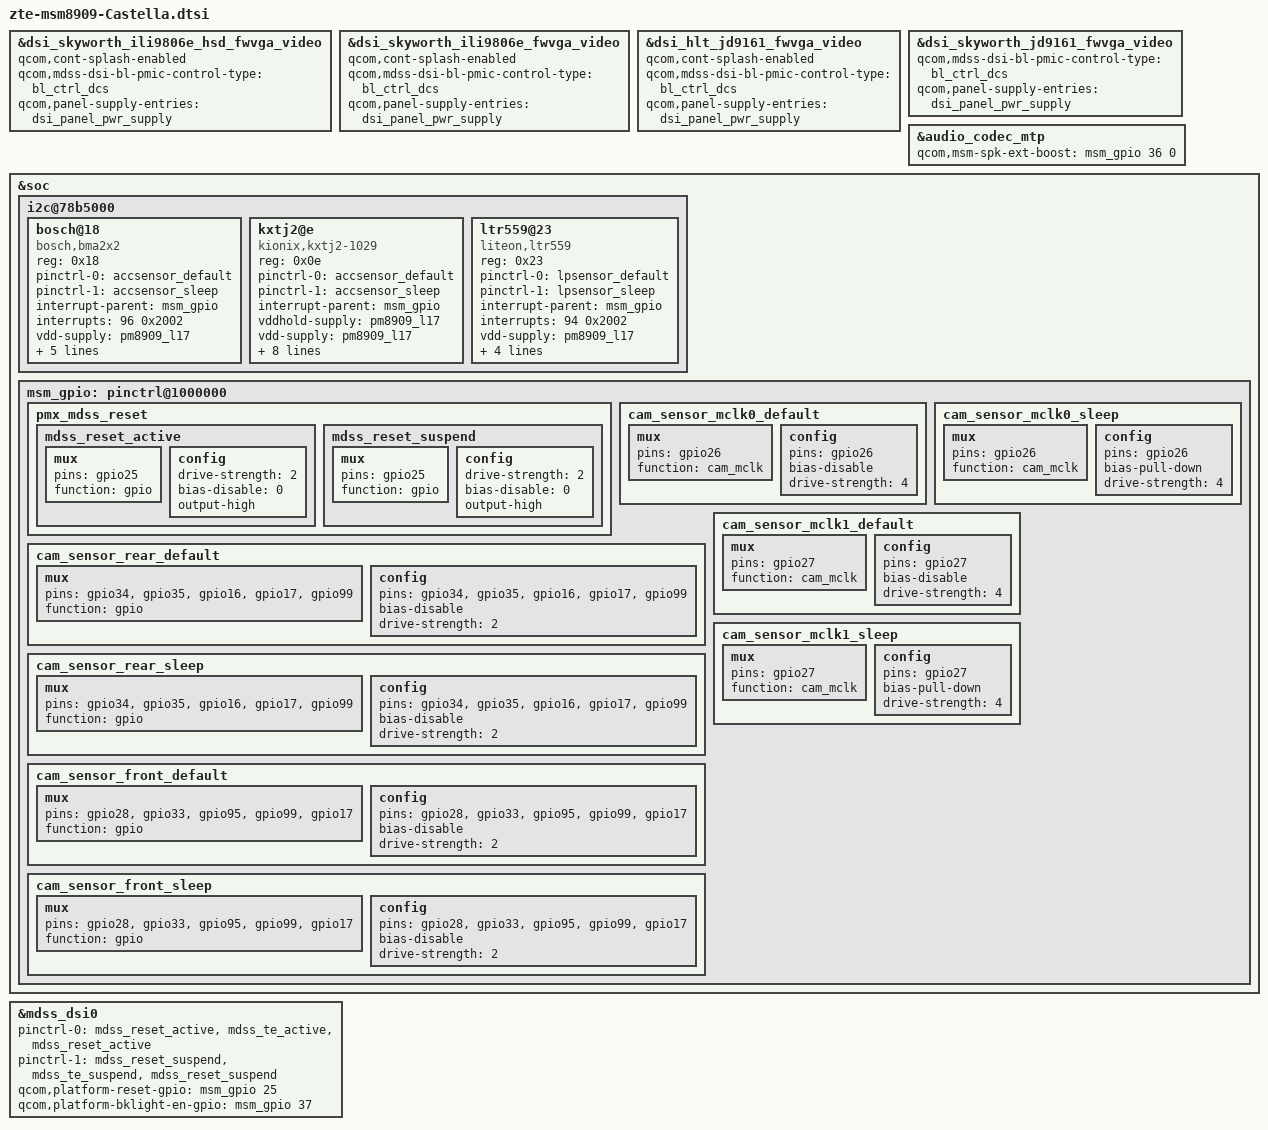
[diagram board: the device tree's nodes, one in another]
#include "dsi-panel-zte-skyworth-hsd-ili9806e-fwvga-video.dtsi"
#include "dsi-panel-zte-skyworth-ili9806e-cpt-5p0-fwvga-video.dtsi"
#include "dsi-panel-zte-helitai-hsd-jd9161-fwvga-video.dtsi"
#include "dsi_panel_zte_skyworth_jd9161_cpt_5p0_fwvga_video.dtsi"
#include "touch-key-backlight-castella.dtsi"

&dsi_skyworth_ili9806e_hsd_fwvga_video {
	qcom,cont-splash-enabled;
	qcom,mdss-dsi-bl-pmic-control-type = "bl_ctrl_dcs";
	qcom,panel-supply-entries = <&dsi_panel_pwr_supply>;
};

&dsi_skyworth_ili9806e_fwvga_video {
	qcom,cont-splash-enabled;
	qcom,mdss-dsi-bl-pmic-control-type = "bl_ctrl_dcs";
	qcom,panel-supply-entries = <&dsi_panel_pwr_supply>;
};

&dsi_hlt_jd9161_fwvga_video {
	qcom,cont-splash-enabled;
	qcom,mdss-dsi-bl-pmic-control-type = "bl_ctrl_dcs";
	qcom,panel-supply-entries = <&dsi_panel_pwr_supply>;
};

&dsi_skyworth_jd9161_fwvga_video {
	qcom,mdss-dsi-bl-pmic-control-type = "bl_ctrl_dcs";
	qcom,panel-supply-entries = <&dsi_panel_pwr_supply>;
};

&audio_codec_mtp {
	qcom,msm-spk-ext-boost = <&msm_gpio 36 0>;
};

&soc {
	i2c@78b5000 { /* BLSP1 QUP1 */
		bosch@18 { /* Accelerometer sensor */
			compatible = "bosch,bma2x2";
			reg = <0x18>;
			pinctrl-names = "default", "sleep";
			pinctrl-0 = <&accsensor_default>;
			pinctrl-1 = <&accsensor_sleep>;
			interrupt-parent = <&msm_gpio>;
			interrupts = <96 0x2002>;
			vdd-supply = <&pm8909_l17>;
			vio-supply = <&pm8909_l6>;
			bosch,init-interval = <200>;
			bosch,place = <5>;
			bosch,gpio-int1 = <&msm_gpio 96 0x2002>;
			bosch,gpio-int2 = <&msm_gpio 65 0x2002>;
		};
		kxtj2@e {
			compatible = "kionix,kxtj2-1029";
			reg = <0x0e>;
			pinctrl-names = "default", "sleep";
			pinctrl-0 = <&accsensor_default>;
			pinctrl-1 = <&accsensor_sleep>;
			interrupt-parent = <&msm_gpio>;
			/*interrupts = <96 0x2>;*/
			vddhold-supply = <&pm8909_l17>;
			vdd-supply = <&pm8909_l17>;
			vio-supply = <&pm8909_l6>;
			kionix,gpio-int = <&msm_gpio 96 0x2>;
			kionix,min_interval = <5>;
			kionix,poll_interval = <100>;
			kionix,accel_direction = <5>;
			kionix,accel_irq_use_drdy = <0>;
			/*0 is 12BIT,	1 is 8BIT,	2 is 6BIT*/
			kionix,accel_res = <0>;
			/*0 is 2g,	1 is 4g,	2 is 6g,	3 is 8g*/
			kionix,accel_g_range =	<0>;
		};
		ltr559@23 {
			compatible = "liteon,ltr559";
			reg = <0x23>;
			pinctrl-names = "lpsensor_default", "lpsensor_sleep";
			pinctrl-0 = <&lpsensor_default>;
			pinctrl-1 = <&lpsensor_sleep>;
			interrupt-parent = <&msm_gpio>;
			interrupts = <94 0x2002>;
			vdd-supply = <&pm8909_l17>;
			vio-supply = <&pm8909_l6>;
			liteon,irq-gpio = <&msm_gpio 94 0x2002>;
			liteon,highthr = <1500>;
			liteon,lowthr = <1200>;
		};
	};

	msm_gpio: pinctrl@1000000 {
		pmx_mdss_reset {
			mdss_reset_active: mdss_reset_active {
				mux {
					pins = "gpio25";
					function = "gpio";
				};

				config {
					drive-strength = <2>; /* 2mA */
					bias-disable = <0>; /* no pull */
					output-high;
				};
			};

			mdss_reset_suspend: mdss_reset_suspend {
				mux {
					pins = "gpio25";
					function = "gpio";
				};

				config {
					drive-strength = <2>; /* 2 mA */
					bias-disable = <0>; /* no pull */
					output-high;
				};
			};
		};
		cam_sensor_mclk0_default: cam_sensor_mclk0_default {
			/* MCLK0 */
			mux {
				/* CLK, DATA */
				pins = "gpio26";
				function = "cam_mclk";
			};

			config {
				pins = "gpio26";
				bias-disable; /* No PULL */
				drive-strength = <4>; /* 4 MA */
			};
		};

		cam_sensor_mclk0_sleep: cam_sensor_mclk0_sleep {
			/* MCLK0 */
			mux {
				/* CLK, DATA */
				pins = "gpio26";
				function = "cam_mclk";
			};

			config {
				pins = "gpio26";
				bias-pull-down; /* PULL DOWN */
				drive-strength = <4>; /* 4 MA */
			};
		};

		cam_sensor_rear_default: cam_sensor_rear_default {
			/* RESET, STANDBY */
			mux {
				pins = "gpio34","gpio35","gpio16","gpio17","gpio99";
				function = "gpio";
			};

			config {
				pins = "gpio34","gpio35","gpio16","gpio17","gpio99";
				bias-disable; /* No PULL */
				drive-strength = <2>; /* 2 MA */
			};
		};

		cam_sensor_rear_sleep: cam_sensor_rear_sleep {
			/* RESET, STANDBY */
			mux {
				pins = "gpio34","gpio35","gpio16","gpio17","gpio99";
				function = "gpio";
			};

			config {
				pins = "gpio34","gpio35","gpio16","gpio17","gpio99";
				bias-disable; /* No PULL */
				drive-strength = <2>; /* 2 MA */
			};
		};

		cam_sensor_mclk1_default: cam_sensor_mclk1_default {
			/* MCLK1 */
			mux {
				/* CLK, DATA */
				pins = "gpio27";
				function = "cam_mclk";
			};

			config {
				pins = "gpio27";
				bias-disable; /* No PULL */
				drive-strength = <4>; /* 4 MA */
			};
		};

		cam_sensor_mclk1_sleep: cam_sensor_mclk1_sleep {
			/* MCLK1 */
			mux {
				/* CLK, DATA */
				pins = "gpio27";
				function = "cam_mclk";
			};

			config {
				pins = "gpio27";
				bias-pull-down; /* PULL DOWN */
				drive-strength = <4>; /* 4 MA */
			};
		};

		cam_sensor_front_default: cam_sensor_front_default {
			/* RESET, STANDBY */
			mux {
				pins = "gpio28","gpio33","gpio95","gpio99","gpio17";
				function = "gpio";
			};

			config {
				pins = "gpio28","gpio33","gpio95","gpio99","gpio17";
				bias-disable; /* No PULL */
				drive-strength = <2>; /* 2 MA */
			};
		};

		cam_sensor_front_sleep: cam_sensor_front_sleep {
			/* RESET, STANDBY */
			mux {
				pins = "gpio28","gpio33","gpio95","gpio99","gpio17";
				function = "gpio";
};

			config {
				pins = "gpio28","gpio33","gpio95","gpio99","gpio17";
				bias-disable; /* No PULL */
				drive-strength = <2>; /* 2 MA */
			};
		};
	};
};
&mdss_dsi0 {
	pinctrl-names = "mdss_default", "mdss_sleep";
	pinctrl-0 = <&mdss_reset_active &mdss_te_active &mdss_reset_active>;
	pinctrl-1 = <&mdss_reset_suspend &mdss_te_suspend  &mdss_reset_suspend>;

	qcom,platform-reset-gpio = <&msm_gpio 25 0>;
	qcom,platform-bklight-en-gpio = <&msm_gpio 37 0>;
};
